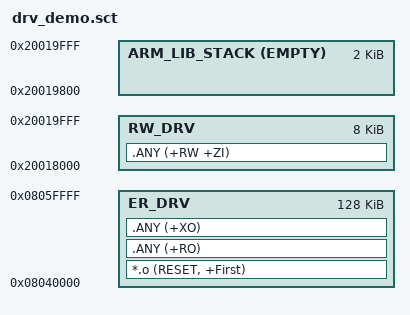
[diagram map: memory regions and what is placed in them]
; *************************************************************
; *** SVCrtOS Driver SDK ???????????? Scatter File         ***
; *** ??????????????????? ROM ???? 0x08040000             ***
; *** RAM ??? 0x20018000 ?? 8KB?????????????????         ***
; *************************************************************

LR_DRV 0x08040000 0x00020000  {        ; ???? ROM ???? 128KB
  ER_DRV 0x08040000 0x00020000  {
   *.o (RESET, +First)                 ; DRVSTART ???????????????
   .ANY (+RO)
   .ANY (+XO)
  }
  RW_DRV 0x20018000 0x00002000  {      ; ???? RAM ???? 8KB
   .ANY (+RW +ZI)
  }
  ARM_LIB_STACK 0x2001A000 EMPTY -0x800 {   ; ????? 2KB
  }
}
